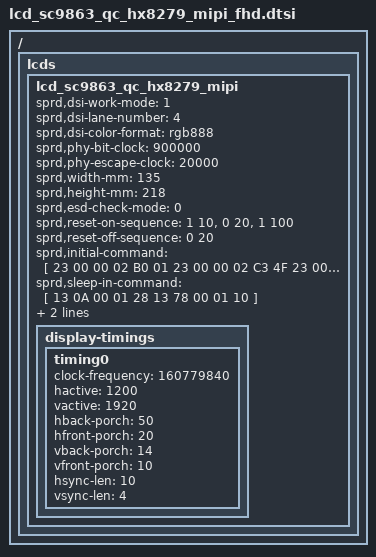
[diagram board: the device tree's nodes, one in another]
/ { lcds {
	lcd_sc9863_qc_hx8279_mipi: lcd_sc9863_qc_hx8279_mipi {

		sprd,dsi-work-mode = <1>;
		sprd,dsi-lane-number = <4>;
		sprd,dsi-color-format = "rgb888";

		sprd,phy-bit-clock = <900000>;
		sprd,phy-escape-clock = <20000>;

		sprd,width-mm = <135>;
		sprd,height-mm = <218>;

		sprd,esd-check-mode = <0>;

		sprd,reset-on-sequence = <1 10>, <0 20>, <1 100>;
		sprd,reset-off-sequence = <0 20>;


		sprd,initial-command = [
				//page1
			  23 00 00 02 B0 01//初始化开始
			  23 00 00 02 C3 4F
			  23 00 00 02 C4 40
			  23 00 00 02 C5 40       
			  23 00 00 02 C6 40         
			  23 00 00 02 C7 40
			  23 00 00 02 C8 4D    
			  23 00 00 02 C9 52
			  23 00 00 02 CA 51
			  23 00 00 02 CD 5D
			  23 00 00 02 CE 5B
			  23 00 00 02 CF 4B
			  23 00 00 02 D0 49
			  23 00 00 02 D1 47
			  23 00 00 02 D2 45
			  23 00 00 02 D3 41
			  23 00 00 02 D7 50
			  23 00 00 02 D8 40
			  23 00 00 02 D9 40
			  23 00 00 02 DA 40
			  23 00 00 02 DB 40
			  23 00 00 02 DC 4E
			  23 00 00 02 DD 52
			  23 00 00 02 DE 51
			  23 00 00 02 E1 5E
			  23 00 00 02 E2 5C
			  23 00 00 02 E3 4C
			  23 00 00 02 E4 4A
			  23 00 00 02 E5 48
			  23 00 00 02 E6 46
			  23 00 00 02 E7 42
			  23 00 00 02 B0 03
			  23 00 00 02 BE 03
			  23 00 00 02 CC 44
			  23 00 00 02 C8 07
			  23 00 00 02 C9 05
			  23 00 00 02 CA 42
			  23 00 00 02 CD 3E
			  23 00 00 02 CF 60
			  23 00 00 02 D2 04
			  23 00 00 02 D3 04
			  23 00 00 02 D4 01
			  23 00 00 02 D5 00
			  23 00 00 02 D6 03
			  23 00 00 02 D7 04
			  23 00 00 02 D9 01
			  23 00 00 02 DB 01
			  23 00 00 02 E4 F0
			  23 00 00 02 E5 0A
			  23 00 00 02 B0 00	//PAGE0
			  23 00 00 02 BD 44
			  23 00 00 02 C2 0C
			  23 00 00 02 C4 0C
			  23 00 00 02 B0 02
			  23 00 00 02 C0 00
			  23 00 00 02 C1 0A
			  23 00 00 02 C3 20
			  23 00 00 02 C3 20
			  23 00 00 02 C4 1F
			  23 00 00 02 C5 1E
			  23 00 00 02 C6 1D
			  23 00 00 02 C7 1C
			  23 00 00 02 C8 19
			  23 00 00 02 C9 17
			  23 00 00 02 CA 17
			  23 00 00 02 CB 18
			  23 00 00 02 CC 1A
			  23 00 00 02 CD 1E
			  23 00 00 02 CE 20
			  23 00 00 02 CF 23
			  23 00 00 02 D0 07
			  23 00 00 02 D1 00
			  23 00 00 02 D2 00
			  23 00 00 02 D3 0A
			  23 00 00 02 D4 13
			  23 00 00 02 D5 20
			  23 00 00 02 D6 1F
			  23 00 00 02 D7 1E
			  23 00 00 02 D8 1D
			  23 00 00 02 D9 1C
			  23 00 00 02 DA 19
			  23 00 00 02 DB 17
			  23 00 00 02 DC 17
			  23 00 00 02 DD 18
			  23 00 00 02 DE 1A
			  23 00 00 02 DF 1E
			  23 00 00 02 E0 20
			  23 00 00 02 E1 23
			  23 00 00 02 E2 07//初始化结束
			13 78 00 01 11
			13 64 00 01 29
			];
		sprd,sleep-in-command = [
			13 0A 00 01 28
			13 78 00 01 10
			];
		sprd,sleep-out-command = [
			13 78 00 01 11
			13 64 00 01 29
			];

		display-timings {
			timing0 {
			clock-frequency = <160779840>;
			hactive = <1200>;
			vactive = <1920>;
			hback-porch = <50>;
			hfront-porch = <20>;
			vback-porch = <14>;
			vfront-porch = <10>;
			hsync-len = <10>;
			vsync-len = <4>;
			};
		};
	};
};};

